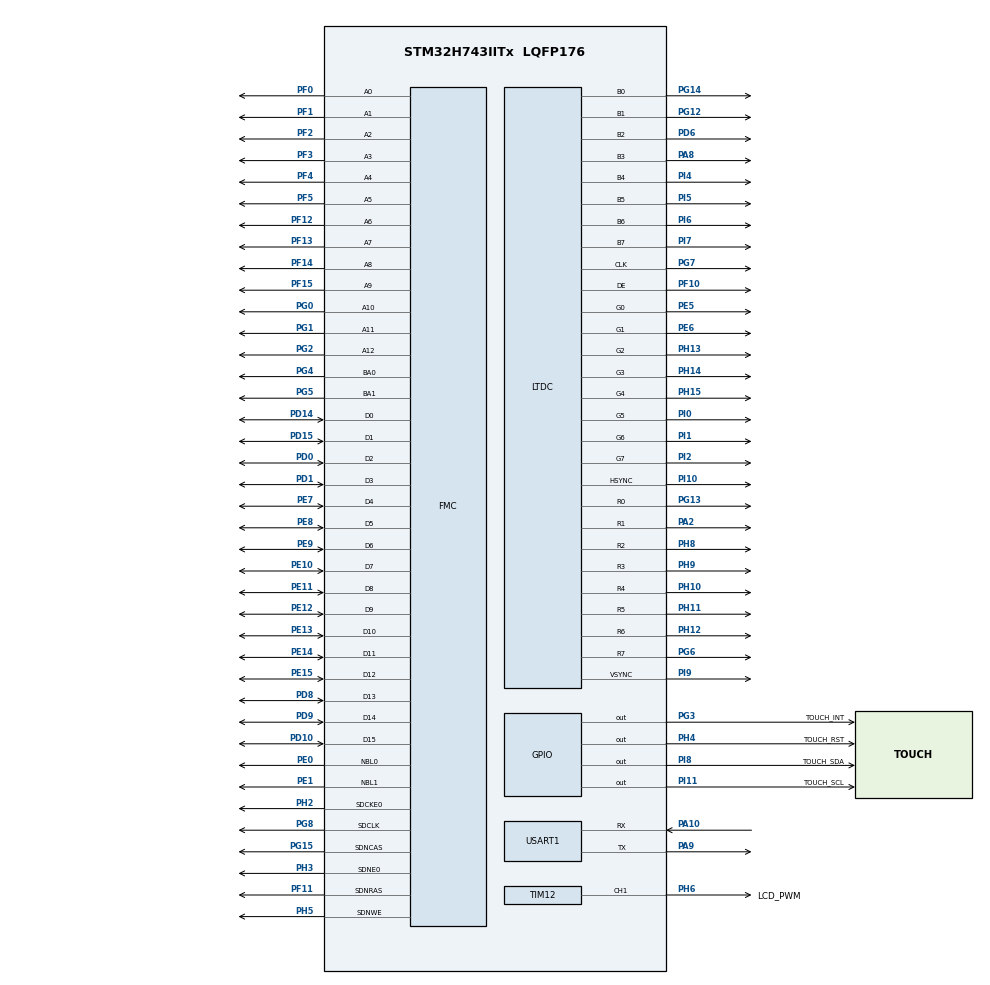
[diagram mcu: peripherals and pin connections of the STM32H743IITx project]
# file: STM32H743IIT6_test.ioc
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CORTEX_M7.CPU_DCache=Enabled
CORTEX_M7.CPU_ICache=Enabled
CORTEX_M7.Enable-Cortex_Memory_Protection_Unit_Region0_Settings=MPU_REGION_ENABLE
CORTEX_M7.IsCacheable-Cortex_Memory_Protection_Unit_Region0_Settings=MPU_ACCESS_CACHEABLE
CORTEX_M7.MPU_Control=MPU_PRIVILEGED_DEFAULT
CORTEX_M7.Size-Cortex_Memory_Protection_Unit_Region0_Settings=MPU_REGION_SIZE_32MB
CORTEX_M7.default_mode_Activation=0
DMA2D.ColorMode=DMA2D_OUTPUT_RGB565
DMA2D.Mode=DMA2D_R2M
FMC.CASLatency1=FMC_SDRAM_CAS_LATENCY_3
FMC.ColumnBitsNumber1=FMC_SDRAM_COLUMN_BITS_NUM_9
FMC.ExitSelfRefreshDelay1=9
FMC.LoadToActiveDelay1=2
FMC.RCDDelay1=3
FMC.RPDelay1=3
FMC.ReadBurst1=FMC_SDRAM_RBURST_ENABLE
FMC.ReadPipeDelay1=FMC_SDRAM_RPIPE_DELAY_1
FMC.RowCycleDelay1=8
FMC.SDClockPeriod1=FMC_SDRAM_CLOCK_PERIOD_2
FMC.SelfRefreshTime1=6
FMC.WriteRecoveryTime1=3
LTDC.ActiveH=272
LTDC.ActiveW=480
LTDC.Alpha_L0=255
LTDC.FBStartAdress_L0=0xC0000000
LTDC.HBP=43
LTDC.HFP=8
LTDC.HSync=1
LTDC.ImageHeight_L0=272
LTDC.ImageWidth_L0=480
LTDC.Layers=0
LTDC.PixelFormat_L0=LTDC_PIXEL_FORMAT_RGB565
LTDC.VBP=12
LTDC.VFP=8
LTDC.VSync=1
LTDC.WindowX1_L0=480
LTDC.WindowY1_L0=272
Mcu.Family=STM32H7
Mcu.Name=STM32H743IITx
Mcu.Package=LQFP176
NVIC.PriorityGroup=NVIC_PRIORITYGROUP_4
NVIC.USART1_IRQn=true\:0\:0\:false\:false\:true\:true\:true\:true
PA10.Mode=Asynchronous
PA10.Signal=USART1_RX
PA13\ (JTMS/SWDIO).Mode=Serial_Wire
PA13\ (JTMS/SWDIO).Signal=DEBUG_JTMS-SWDIO
PA14\ (JTCK/SWCLK).Mode=Serial_Wire
PA14\ (JTCK/SWCLK).Signal=DEBUG_JTCK-SWCLK
PA2.GPIO_Speed=GPIO_SPEED_FREQ_VERY_HIGH
PA2.Mode=RGB888
PA2.Signal=LTDC_R1
PA8.GPIO_Speed=GPIO_SPEED_FREQ_VERY_HIGH
PA8.Mode=RGB888
PA8.Signal=LTDC_B3
PA9.Mode=Asynchronous
PA9.Signal=USART1_TX
PD0.Signal=FMC_D2_DA2
PD1.Signal=FMC_D3_DA3
PD10.Signal=FMC_D15_DA15
PD14.Signal=FMC_D0_DA0
PD15.Signal=FMC_D1_DA1
PD6.GPIO_Speed=GPIO_SPEED_FREQ_VERY_HIGH
PD6.Mode=RGB888
PD6.Signal=LTDC_B2
PD8.Signal=FMC_D13_DA13
PD9.Signal=FMC_D14_DA14
PE0.Signal=FMC_NBL0
PE1.Signal=FMC_NBL1
PE10.Signal=FMC_D7_DA7
PE11.Signal=FMC_D8_DA8
PE12.Signal=FMC_D9_DA9
PE13.Signal=FMC_D10_DA10
PE14.Signal=FMC_D11_DA11
PE15.Signal=FMC_D12_DA12
PE5.GPIO_Speed=GPIO_SPEED_FREQ_VERY_HIGH
PE5.Mode=RGB888
PE5.Signal=LTDC_G0
PE6.GPIO_Speed=GPIO_SPEED_FREQ_VERY_HIGH
PE6.Mode=RGB888
PE6.Signal=LTDC_G1
PE7.Signal=FMC_D4_DA4
PE8.Signal=FMC_D5_DA5
PE9.Signal=FMC_D6_DA6
PF0.Signal=FMC_A0
PF1.Signal=FMC_A1
PF10.GPIO_Speed=GPIO_SPEED_FREQ_VERY_HIGH
PF10.Mode=RGB888
PF10.Signal=LTDC_DE
PF11.Signal=FMC_SDNRAS
PF12.Signal=FMC_A6
PF13.Signal=FMC_A7
PF14.Signal=FMC_A8
PF15.Signal=FMC_A9
PF2.Signal=FMC_A2
PF3.Signal=FMC_A3
PF4.Signal=FMC_A4
PF5.Signal=FMC_A5
PG0.Signal=FMC_A10
PG1.Signal=FMC_A11
PG12.GPIO_Speed=GPIO_SPEED_FREQ_VERY_HIGH
PG12.Mode=RGB888
PG12.Signal=LTDC_B1
PG13.GPIO_Speed=GPIO_SPEED_FREQ_VERY_HIGH
PG13.Mode=RGB888
PG13.Signal=LTDC_R0
PG14.GPIO_Speed=GPIO_SPEED_FREQ_VERY_HIGH
PG14.Mode=RGB888
PG14.Signal=LTDC_B0
PG15.Signal=FMC_SDNCAS
PG2.Signal=FMC_A12
PG3.GPIO_Label=TOUCH_INT
PG3.GPIO_ModeDefaultOutputPP=GPIO_MODE_OUTPUT_PP
PG3.GPIO_PuPd=GPIO_PULLUP
PG3.Signal=GPIO_Output
PG4.Signal=FMC_A14_BA0
PG5.Signal=FMC_A15_BA1
PG6.GPIO_Speed=GPIO_SPEED_FREQ_VERY_HIGH
PG6.Mode=RGB888
PG6.Signal=LTDC_R7
PG7.GPIO_Speed=GPIO_SPEED_FREQ_VERY_HIGH
PG7.Mode=RGB888
PG7.Signal=LTDC_CLK
PG8.Signal=FMC_SDCLK
PH0-OSC_IN\ (PH0).Mode=HSE-External-Oscillator
PH0-OSC_IN\ (PH0).Signal=RCC_OSC_IN
PH1-OSC_OUT\ (PH1).Mode=HSE-External-Oscillator
PH1-OSC_OUT\ (PH1).Signal=RCC_OSC_OUT
PH10.GPIO_Speed=GPIO_SPEED_FREQ_VERY_HIGH
PH10.Mode=RGB888
PH10.Signal=LTDC_R4
PH11.GPIO_Speed=GPIO_SPEED_FREQ_VERY_HIGH
PH11.Mode=RGB888
PH11.Signal=LTDC_R5
PH12.GPIO_Speed=GPIO_SPEED_FREQ_VERY_HIGH
PH12.Mode=RGB888
PH12.Signal=LTDC_R6
PH13.GPIO_Speed=GPIO_SPEED_FREQ_VERY_HIGH
PH13.Mode=RGB888
PH13.Signal=LTDC_G2
PH14.GPIO_Speed=GPIO_SPEED_FREQ_VERY_HIGH
PH14.Mode=RGB888
PH14.Signal=LTDC_G3
PH15.GPIO_Speed=GPIO_SPEED_FREQ_VERY_HIGH
PH15.Mode=RGB888
PH15.Signal=LTDC_G4
PH2.Mode=SdramChipSelect1_1
PH2.Signal=FMC_SDCKE0
PH3.Mode=SdramChipSelect1_1
PH3.Signal=FMC_SDNE0
PH4.GPIO_Label=TOUCH_RST
PH4.GPIO_PuPd=GPIO_PULLUP
PH4.PinState=GPIO_PIN_SET
PH4.Signal=GPIO_Output
PH5.Signal=FMC_SDNWE
PH6.GPIO_Label=LCD_PWM
PH6.Signal=S_TIM12_CH1
PH8.GPIO_Speed=GPIO_SPEED_FREQ_VERY_HIGH
PH8.Mode=RGB888
PH8.Signal=LTDC_R2
PH9.GPIO_Speed=GPIO_SPEED_FREQ_VERY_HIGH
PH9.Mode=RGB888
PH9.Signal=LTDC_R3
PI0.GPIO_Speed=GPIO_SPEED_FREQ_VERY_HIGH
PI0.Mode=RGB888
PI0.Signal=LTDC_G5
PI1.GPIO_Speed=GPIO_SPEED_FREQ_VERY_HIGH
PI1.Mode=RGB888
PI1.Signal=LTDC_G6
PI10.GPIO_Speed=GPIO_SPEED_FREQ_VERY_HIGH
PI10.Mode=RGB888
PI10.Signal=LTDC_HSYNC
PI11.GPIO_Label=TOUCH_SCL
PI11.GPIO_ModeDefaultOutputPP=GPIO_MODE_OUTPUT_OD
PI11.GPIO_PuPd=GPIO_NOPULL
PI11.PinState=GPIO_PIN_SET
PI11.Signal=GPIO_Output
PI2.GPIO_Speed=GPIO_SPEED_FREQ_VERY_HIGH
PI2.Mode=RGB888
PI2.Signal=LTDC_G7
PI4.GPIO_Speed=GPIO_SPEED_FREQ_VERY_HIGH
PI4.Mode=RGB888
PI4.Signal=LTDC_B4
PI5.GPIO_Speed=GPIO_SPEED_FREQ_VERY_HIGH
PI5.Mode=RGB888
PI5.Signal=LTDC_B5
PI6.GPIO_Speed=GPIO_SPEED_FREQ_VERY_HIGH
PI6.Mode=RGB888
PI6.Signal=LTDC_B6
PI7.GPIO_Speed=GPIO_SPEED_FREQ_VERY_HIGH
PI7.Mode=RGB888
PI7.Signal=LTDC_B7
PI8.GPIO_Label=TOUCH_SDA
PI8.GPIO_ModeDefaultOutputPP=GPIO_MODE_OUTPUT_OD
PI8.GPIO_PuPd=GPIO_NOPULL
PI8.PinState=GPIO_PIN_SET
PI8.Signal=GPIO_Output
PI9.GPIO_Speed=GPIO_SPEED_FREQ_VERY_HIGH
PI9.Mode=RGB888
PI9.Signal=LTDC_VSYNC
ProjectManager.HeapSize=0x2000
ProjectManager.StackSize=0x1000
ProjectManager.TargetToolchain=MDK-ARM V5.32
RCC.ADCFreq_Value=50390625
RCC.APB1Freq_Value=120000000
RCC.APB2Freq_Value=120000000
RCC.APB3Freq_Value=120000000
RCC.APB4Freq_Value=120000000
RCC.CortexFreq_Value=480000000
RCC.D1PPRE=RCC_APB3_DIV2
RCC.D2PPRE1=RCC_APB1_DIV2
RCC.D2PPRE2=RCC_APB2_DIV2
RCC.D3PPRE=RCC_APB4_DIV2
RCC.DIVM1=5
RCC.DIVN1=192
RCC.DIVN3=192
RCC.DIVR3=15
RCC.HCLKFreq_Value=240000000
RCC.HPRE=RCC_HCLK_DIV2
RCC.HSE_VALUE=25000000
RCC.PLLSourceVirtual=RCC_PLLSOURCE_HSE
RCC.SYSCLKFreq_VALUE=480000000
RCC.SYSCLKSource=RCC_SYSCLKSOURCE_PLLCLK
RCC.USBFreq_Value=480000000
SH.FMC_A0.0=FMC_A0,13b-sda1
SH.FMC_A1.0=FMC_A1,13b-sda1
SH.FMC_A10.0=FMC_A10,13b-sda1
SH.FMC_A11.0=FMC_A11,13b-sda1
SH.FMC_A12.0=FMC_A12,13b-sda1
SH.FMC_A14_BA0.0=FMC_BA0,FourSdramBanks1
SH.FMC_A15_BA1.0=FMC_BA1,FourSdramBanks1
SH.FMC_A2.0=FMC_A2,13b-sda1
SH.FMC_A3.0=FMC_A3,13b-sda1
SH.FMC_A4.0=FMC_A4,13b-sda1
SH.FMC_A5.0=FMC_A5,13b-sda1
SH.FMC_A6.0=FMC_A6,13b-sda1
SH.FMC_A7.0=FMC_A7,13b-sda1
SH.FMC_A8.0=FMC_A8,13b-sda1
SH.FMC_A9.0=FMC_A9,13b-sda1
SH.FMC_D0_DA0.0=FMC_D0,sd-16b-d1
SH.FMC_D10_DA10.0=FMC_D10,sd-16b-d1
SH.FMC_D11_DA11.0=FMC_D11,sd-16b-d1
SH.FMC_D12_DA12.0=FMC_D12,sd-16b-d1
SH.FMC_D13_DA13.0=FMC_D13,sd-16b-d1
SH.FMC_D14_DA14.0=FMC_D14,sd-16b-d1
SH.FMC_D15_DA15.0=FMC_D15,sd-16b-d1
SH.FMC_D1_DA1.0=FMC_D1,sd-16b-d1
SH.FMC_D2_DA2.0=FMC_D2,sd-16b-d1
SH.FMC_D3_DA3.0=FMC_D3,sd-16b-d1
SH.FMC_D4_DA4.0=FMC_D4,sd-16b-d1
SH.FMC_D5_DA5.0=FMC_D5,sd-16b-d1
SH.FMC_D6_DA6.0=FMC_D6,sd-16b-d1
SH.FMC_D7_DA7.0=FMC_D7,sd-16b-d1
SH.FMC_D8_DA8.0=FMC_D8,sd-16b-d1
SH.FMC_D9_DA9.0=FMC_D9,sd-16b-d1
SH.FMC_NBL0.0=FMC_NBL0,Sd2ByteEnable1
SH.FMC_NBL1.0=FMC_NBL1,Sd2ByteEnable1
SH.FMC_SDCLK.0=FMC_SDCLK,13b-sda1
SH.FMC_SDNCAS.0=FMC_SDNCAS,13b-sda1
SH.FMC_SDNRAS.0=FMC_SDNRAS,13b-sda1
SH.FMC_SDNWE.0=FMC_SDNWE,13b-sda1
SH.S_TIM12_CH1.0=TIM12_CH1,PWM Generation1 CH1
TIM12.Channel-PWM\ Generation1\ CH1=TIM_CHANNEL_1
TIM12.Period=500-1
TIM12.Prescaler=240-1
TIM12.Pulse-PWM\ Generation1\ CH1=50
USART1.VirtualMode-Asynchronous=VM_ASYNC
VP_DMA2D_VS_DMA2D.Mode=DMA2D_Activate
VP_MEMORYMAP_VS_MEMORYMAP.Mode=CurAppReg
VP_TIM12_VS_ClockSourceINT.Mode=Internal
board=custom

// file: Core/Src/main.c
/* USER CODE BEGIN Header */
/**
  ******************************************************************************
  * @file           : main.c
  * @brief          : Main program body
  ******************************************************************************
  * @attention
  *
  * Copyright (c) 2025 STMicroelectronics.
  * All rights reserved.
  *
  * This software is licensed under terms that can be found in the LICENSE file
  * in the root directory of this software component.
  * If no LICENSE file comes with this software, it is provided AS-IS.
  *
  ******************************************************************************
  */
/* USER CODE END Header */
#include "main.h"
#include "dma2d.h"
#include "ltdc.h"
#include "memorymap.h"
#include "tim.h"
#include "usart.h"
#include "gpio.h"
#include "fmc.h"

/* USER CODE BEGIN Includes */
#include "sdram.h"
#include "lcd_fonts.h"
#include "lcd_image.h"
#include "lcd_rgb.h"
#include "lcd_test.h"
#include "touch_480x272.h"
/* USER CODE END Includes */

void SystemClock_Config(void);
static void MPU_Config(void);

/* USER CODE BEGIN 0 */
/*************************************************************************************************
*	函 数 名:	fputc
*	入口参数:	ch - 要输出的字符 ，  f - 文件指针（这里用不到）
*	返 回 值:	正常时返回字符，出错时返回 EOF（-1）
*	函数功能:	重定向 fputc 函数，目的是使用 printf 函数
*	说    明:	无
*************************************************************************************************/

int fputc(int ch, FILE *f)
{
	HAL_UART_Transmit(&huart1, (uint8_t *)&ch, 1, 100);	// 发送单字节数据
	return (ch);
}
void test_f(void){
	uint16_t time = 1000;	// 延时时间
	uint8_t	i = 0;			// 计数变量

// 绘制初始界面，包括标题、LOGO以及进度条>>>>>

//	LCD_SetBackColor(0xffB9EDF8); 			//	设置背景色，使用自定义颜色
//	LCD_Clear(); 									//	清屏，刷背景色

	LCD_SetTextFont(&CH_Font32);				// 设置3232中文字体,ASCII字体对应为3216
	LCD_SetColor(0xff333333);					//	设置画笔色，使用自定义颜色
	LCD_DisplayText(176, 87,"刷屏测试");	// 显示文本
}

/* USER CODE END 0 */

int main(void)
{

  /* MPU Configuration--------------------------------------------------------*/
  MPU_Config();

  /* Enable the CPU Cache */

  /* Enable I-Cache---------------------------------------------------------*/
  SCB_EnableICache();

  /* Enable D-Cache---------------------------------------------------------*/
  SCB_EnableDCache();

  /* MCU Configuration--------------------------------------------------------*/

  /* Reset of all peripherals, Initializes the Flash interface and the Systick. */
  HAL_Init();

  /* Configure the system clock */
  SystemClock_Config();

  /* Initialize all configured peripherals */
  MX_GPIO_Init();
  MX_FMC_Init();
  MX_USART1_UART_Init();
  MX_LTDC_Init();
  MX_DMA2D_Init();
  MX_TIM12_Init();
  /* USER CODE BEGIN 2 */

	LCD_Init();

	Touch_Init();

	LCD_SetColor(0xff333333);					//	设置画笔色，使用自定义颜色
	LCD_SetBackColor(0xffB9EDF8); 			//	设置背景色，使用自定义颜色
	LCD_Clear(); 									//	清屏，刷背景色

	LCD_SetTextFont(&CH_Font24);			// 设置2424中文字体,ASCII字体对应为2412
	LCD_SetColor(LCD_BLACK);				// 设置画笔颜色

//	LCD_DisplayText( 42,  9,"电电电测电电电电4.3寸电容触摸测试");
//	LCD_DisplayText( 42, 44,"核心板型号：FK743M2-IIcT6");
//	LCD_DisplayText( 42, 79,"屏幕分辨率：480*272");

	LCD_SetBackColor(0xffB9EDF8); 			//	设置背景色，使用自定义颜色
	LCD_Clear(); 									//	清屏，刷背景色

test_f2();
test_f();
//LCD_Test_Clear();
//
//	LCD_DisplayString(44, 114,"X1:      Y1:");
//	LCD_DisplayString(44, 144,"X2:      Y2:");
//	LCD_DisplayString(44, 174,"X3:      Y3:");
//	LCD_DisplayString(44, 204,"X4:      Y4:");
//	LCD_DisplayString(44, 234,"X5:      Y5:");
//
	LCD_SetColor(LCD_RED);	//设置画笔颜色

  /* USER CODE END 2 */

  /* Infinite loop */
  /* USER CODE BEGIN WHILE */
  while (1)
  {
		Touch_Scan();	// 触摸扫描

		if(touchInfo.flag == 1)
		{
		   LCD_DisplayNumber( 80,114,touchInfo.x[0],4);	// 显示第1组坐标
			LCD_DisplayNumber(200,114,touchInfo.y[0],4);

			LCD_DisplayNumber( 80,144,touchInfo.x[1],4);	// 显示第2组坐标
			LCD_DisplayNumber(200,144,touchInfo.y[1],4);

			LCD_DisplayNumber( 80,174,touchInfo.x[2],4);	// 显示第3组坐标
			LCD_DisplayNumber(200,174,touchInfo.y[2],4);

			LCD_DisplayNumber( 80,204,touchInfo.x[3],4);	// 显示第4组坐标
			LCD_DisplayNumber(200,204,touchInfo.y[3],4);

			LCD_DisplayNumber( 80,234,touchInfo.x[4],4);	// 显示第5组坐标
			LCD_DisplayNumber(200,234,touchInfo.y[4],4);
		}
		HAL_Delay(20);	// GT911触摸屏扫描间隔不能小于10ms，建议设置为20ms

//		LCD_Test_Clear();			// ????????
//		LCD_Test_Text();			// ??????????
//		LCD_Test_Variable();		// ???????????????????С??
//		LCD_Test_Color();			// ???????
//		LCD_Test_GrahicTest();	// 2D??λ???
//		LCD_Test_FillRect();		// ??????????
//		LCD_Test_Image();			// ?????????
//
//		LCD_Test_Vertical();		// ??????????
    /* USER CODE END WHILE */

  }
}

void SystemClock_Config(void)
{
  RCC_OscInitTypeDef RCC_OscInitStruct = {0};
  RCC_ClkInitTypeDef RCC_ClkInitStruct = {0};

  /** Supply configuration update enable
  */
  HAL_PWREx_ConfigSupply(PWR_LDO_SUPPLY);

  /** Configure the main internal regulator output voltage
  */
  __HAL_PWR_VOLTAGESCALING_CONFIG(PWR_REGULATOR_VOLTAGE_SCALE0);

  while(!__HAL_PWR_GET_FLAG(PWR_FLAG_VOSRDY)) {}

  /** Initializes the RCC Oscillators according to the specified parameters
  * in the RCC_OscInitTypeDef structure.
  */
  RCC_OscInitStruct.OscillatorType = RCC_OSCILLATORTYPE_HSE;
  RCC_OscInitStruct.HSEState = RCC_HSE_ON;
  RCC_OscInitStruct.PLL.PLLState = RCC_PLL_ON;
  RCC_OscInitStruct.PLL.PLLSource = RCC_PLLSOURCE_HSE;
  RCC_OscInitStruct.PLL.PLLM = 5;
  RCC_OscInitStruct.PLL.PLLN = 192;
  RCC_OscInitStruct.PLL.PLLP = 2;
  RCC_OscInitStruct.PLL.PLLQ = 2;
  RCC_OscInitStruct.PLL.PLLR = 2;
  RCC_OscInitStruct.PLL.PLLRGE = RCC_PLL1VCIRANGE_2;
  RCC_OscInitStruct.PLL.PLLVCOSEL = RCC_PLL1VCOWIDE;
  RCC_OscInitStruct.PLL.PLLFRACN = 0;
  if (HAL_RCC_OscConfig(&RCC_OscInitStruct) != HAL_OK)
  {
    Error_Handler();
  }

  /** Initializes the CPU, AHB and APB buses clocks
  */
  RCC_ClkInitStruct.ClockType = RCC_CLOCKTYPE_HCLK|RCC_CLOCKTYPE_SYSCLK
                              |RCC_CLOCKTYPE_PCLK1|RCC_CLOCKTYPE_PCLK2
                              |RCC_CLOCKTYPE_D3PCLK1|RCC_CLOCKTYPE_D1PCLK1;
  RCC_ClkInitStruct.SYSCLKSource = RCC_SYSCLKSOURCE_PLLCLK;
  RCC_ClkInitStruct.SYSCLKDivider = RCC_SYSCLK_DIV1;
  RCC_ClkInitStruct.AHBCLKDivider = RCC_HCLK_DIV2;
  RCC_ClkInitStruct.APB3CLKDivider = RCC_APB3_DIV2;
  RCC_ClkInitStruct.APB1CLKDivider = RCC_APB1_DIV2;
  RCC_ClkInitStruct.APB2CLKDivider = RCC_APB2_DIV2;
  RCC_ClkInitStruct.APB4CLKDivider = RCC_APB4_DIV2;

  if (HAL_RCC_ClockConfig(&RCC_ClkInitStruct, FLASH_LATENCY_4) != HAL_OK)
  {
    Error_Handler();
  }
}

 /* MPU Configuration */

void MPU_Config(void)
{
  MPU_Region_InitTypeDef MPU_InitStruct = {0};

  /* Disables the MPU */
  HAL_MPU_Disable();

  /** Initializes and configures the Region and the memory to be protected
  */
  MPU_InitStruct.Enable = MPU_REGION_ENABLE;
  MPU_InitStruct.Number = MPU_REGION_NUMBER0;
  MPU_InitStruct.BaseAddress = 0x0;
  MPU_InitStruct.Size = MPU_REGION_SIZE_32MB;
  MPU_InitStruct.SubRegionDisable = 0x0;
  MPU_InitStruct.TypeExtField = MPU_TEX_LEVEL0;
  MPU_InitStruct.AccessPermission = MPU_REGION_NO_ACCESS;
  MPU_InitStruct.DisableExec = MPU_INSTRUCTION_ACCESS_ENABLE;
  MPU_InitStruct.IsShareable = MPU_ACCESS_NOT_SHAREABLE;
  MPU_InitStruct.IsCacheable = MPU_ACCESS_CACHEABLE;
  MPU_InitStruct.IsBufferable = MPU_ACCESS_NOT_BUFFERABLE;

  HAL_MPU_ConfigRegion(&MPU_InitStruct);
  /* Enables the MPU */
  HAL_MPU_Enable(MPU_PRIVILEGED_DEFAULT);

}

void Error_Handler(void)
{
  __disable_irq();
  while (1)
  {
  }
}
